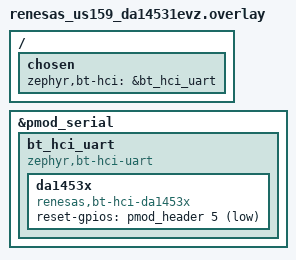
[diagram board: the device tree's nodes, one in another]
/*
 * Copyright (c) 2024 Renesas Electronics Corporation
 *
 * SPDX-License-Identifier: Apache-2.0
 */

/ {
	chosen {
		zephyr,bt-hci = &bt_hci_uart;
	};
};

&pmod_serial {
	status = "okay";

	bt_hci_uart: bt_hci_uart {
		compatible = "zephyr,bt-hci-uart";
		status = "okay";

		da1453x {
			compatible = "renesas,bt-hci-da1453x";
			status = "okay";
			reset-gpios = <&pmod_header 5 GPIO_ACTIVE_LOW>;
		};
	};
};
